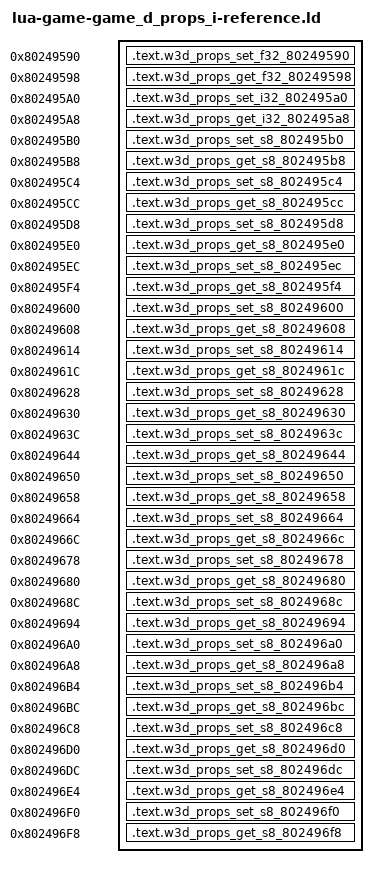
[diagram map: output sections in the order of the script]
/* Generated reference-only placements. All bodies are source-built. */
OUTPUT_FORMAT("elf32-powerpc")
OUTPUT_ARCH(powerpc)
ENTRY(w3d_props_set_f32_80249590)
_SDA_BASE_ = 0x804b2540;
_SDA2_BASE_ = 0x804c2540;
SECTIONS {
  .text.w3d_props_set_f32_80249590 0x80249590 : { *(.text.w3d_props_set_f32_80249590) }
  .text.w3d_props_get_f32_80249598 0x80249598 : { *(.text.w3d_props_get_f32_80249598) }
  .text.w3d_props_set_i32_802495a0 0x802495a0 : { *(.text.w3d_props_set_i32_802495a0) }
  .text.w3d_props_get_i32_802495a8 0x802495a8 : { *(.text.w3d_props_get_i32_802495a8) }
  .text.w3d_props_set_s8_802495b0 0x802495b0 : { *(.text.w3d_props_set_s8_802495b0) }
  .text.w3d_props_get_s8_802495b8 0x802495b8 : { *(.text.w3d_props_get_s8_802495b8) }
  .text.w3d_props_set_s8_802495c4 0x802495c4 : { *(.text.w3d_props_set_s8_802495c4) }
  .text.w3d_props_get_s8_802495cc 0x802495cc : { *(.text.w3d_props_get_s8_802495cc) }
  .text.w3d_props_set_s8_802495d8 0x802495d8 : { *(.text.w3d_props_set_s8_802495d8) }
  .text.w3d_props_get_s8_802495e0 0x802495e0 : { *(.text.w3d_props_get_s8_802495e0) }
  .text.w3d_props_set_s8_802495ec 0x802495ec : { *(.text.w3d_props_set_s8_802495ec) }
  .text.w3d_props_get_s8_802495f4 0x802495f4 : { *(.text.w3d_props_get_s8_802495f4) }
  .text.w3d_props_set_s8_80249600 0x80249600 : { *(.text.w3d_props_set_s8_80249600) }
  .text.w3d_props_get_s8_80249608 0x80249608 : { *(.text.w3d_props_get_s8_80249608) }
  .text.w3d_props_set_s8_80249614 0x80249614 : { *(.text.w3d_props_set_s8_80249614) }
  .text.w3d_props_get_s8_8024961c 0x8024961c : { *(.text.w3d_props_get_s8_8024961c) }
  .text.w3d_props_set_s8_80249628 0x80249628 : { *(.text.w3d_props_set_s8_80249628) }
  .text.w3d_props_get_s8_80249630 0x80249630 : { *(.text.w3d_props_get_s8_80249630) }
  .text.w3d_props_set_s8_8024963c 0x8024963c : { *(.text.w3d_props_set_s8_8024963c) }
  .text.w3d_props_get_s8_80249644 0x80249644 : { *(.text.w3d_props_get_s8_80249644) }
  .text.w3d_props_set_s8_80249650 0x80249650 : { *(.text.w3d_props_set_s8_80249650) }
  .text.w3d_props_get_s8_80249658 0x80249658 : { *(.text.w3d_props_get_s8_80249658) }
  .text.w3d_props_set_s8_80249664 0x80249664 : { *(.text.w3d_props_set_s8_80249664) }
  .text.w3d_props_get_s8_8024966c 0x8024966c : { *(.text.w3d_props_get_s8_8024966c) }
  .text.w3d_props_set_s8_80249678 0x80249678 : { *(.text.w3d_props_set_s8_80249678) }
  .text.w3d_props_get_s8_80249680 0x80249680 : { *(.text.w3d_props_get_s8_80249680) }
  .text.w3d_props_set_s8_8024968c 0x8024968c : { *(.text.w3d_props_set_s8_8024968c) }
  .text.w3d_props_get_s8_80249694 0x80249694 : { *(.text.w3d_props_get_s8_80249694) }
  .text.w3d_props_set_s8_802496a0 0x802496a0 : { *(.text.w3d_props_set_s8_802496a0) }
  .text.w3d_props_get_s8_802496a8 0x802496a8 : { *(.text.w3d_props_get_s8_802496a8) }
  .text.w3d_props_set_s8_802496b4 0x802496b4 : { *(.text.w3d_props_set_s8_802496b4) }
  .text.w3d_props_get_s8_802496bc 0x802496bc : { *(.text.w3d_props_get_s8_802496bc) }
  .text.w3d_props_set_s8_802496c8 0x802496c8 : { *(.text.w3d_props_set_s8_802496c8) }
  .text.w3d_props_get_s8_802496d0 0x802496d0 : { *(.text.w3d_props_get_s8_802496d0) }
  .text.w3d_props_set_s8_802496dc 0x802496dc : { *(.text.w3d_props_set_s8_802496dc) }
  .text.w3d_props_get_s8_802496e4 0x802496e4 : { *(.text.w3d_props_get_s8_802496e4) }
  .text.w3d_props_set_s8_802496f0 0x802496f0 : { *(.text.w3d_props_set_s8_802496f0) }
  .text.w3d_props_get_s8_802496f8 0x802496f8 : { *(.text.w3d_props_get_s8_802496f8) }
  /DISCARD/ : { *(.text*) *(.rodata*) *(.data*) *(.bss*) *(.sdata*) *(.sbss*) *(.comment) }
}
